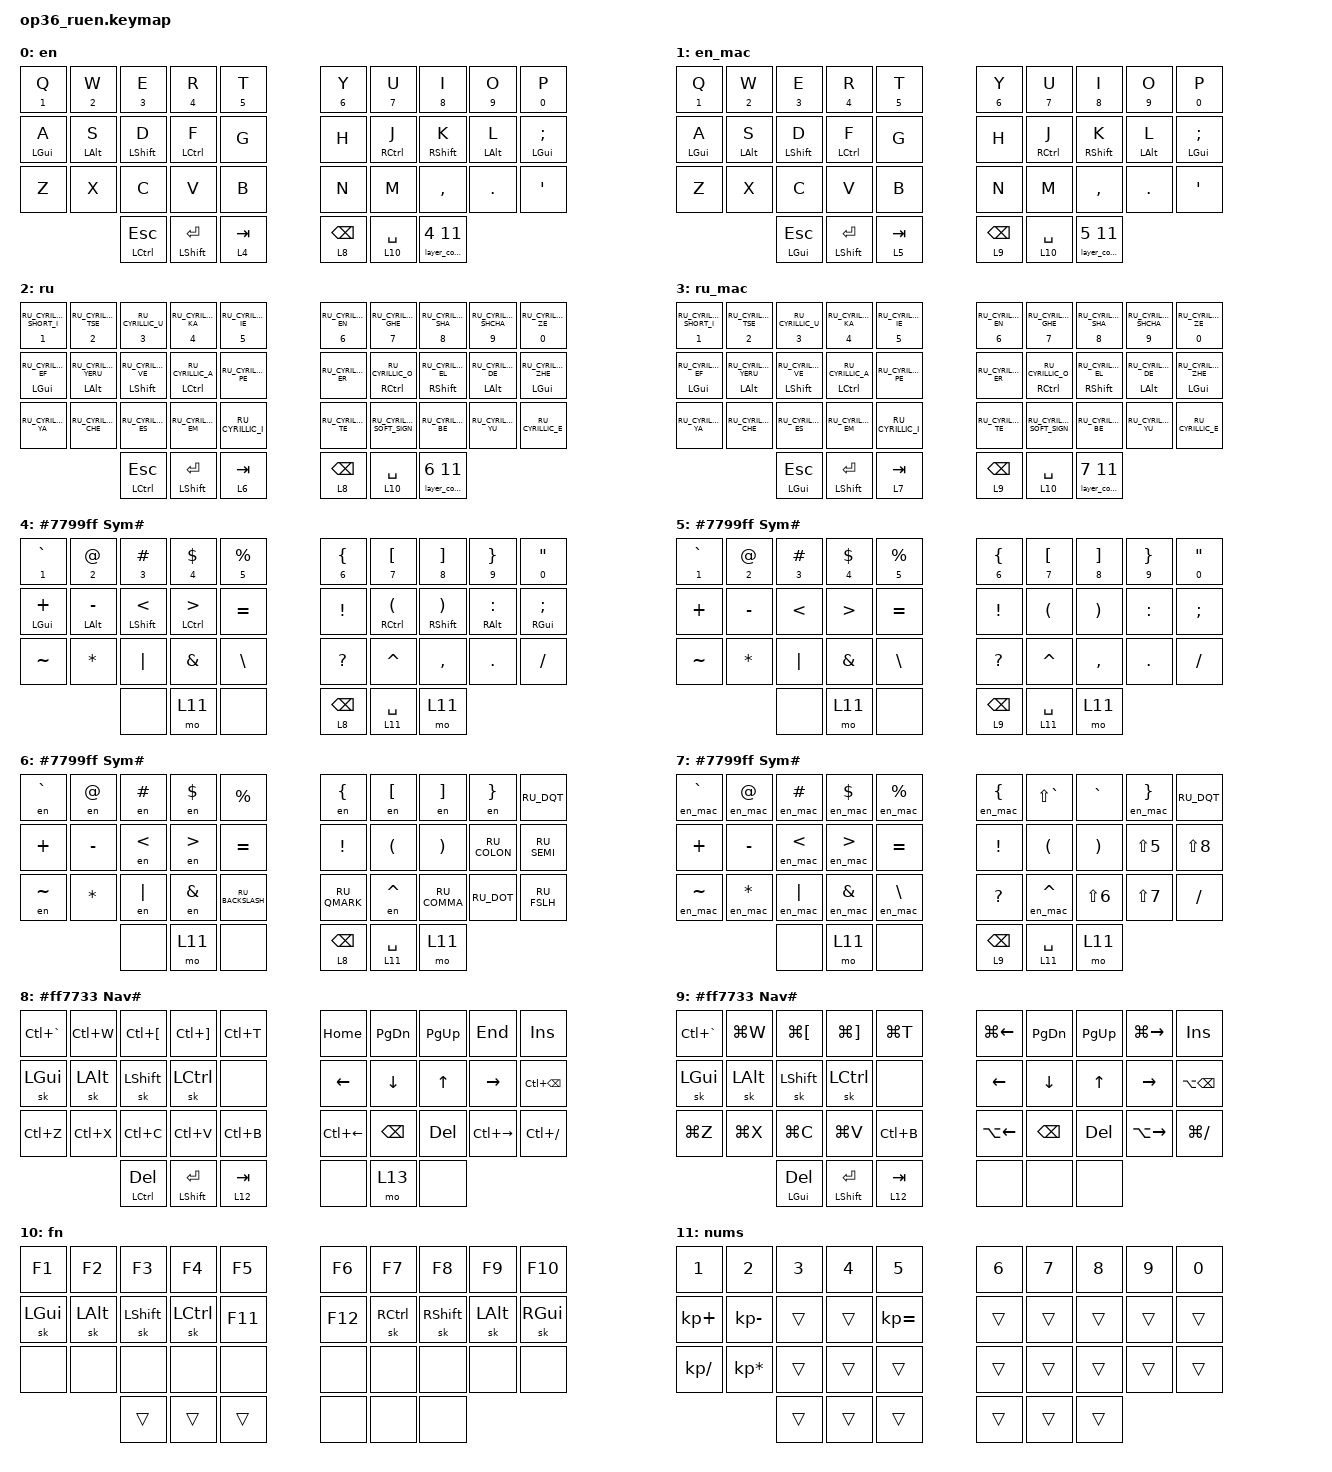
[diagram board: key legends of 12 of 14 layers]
#include "keys_ru.h"
#include <behaviors.dtsi>
#include <dt-bindings/zmk/bt.h>
#include <dt-bindings/zmk/keys.h>
#include <dt-bindings/zmk/outputs.h>
#include <dt-bindings/zmk/pointing.h>

&lt {
    flavor = "balanced";
    tapping-term-ms = <150>;
};

/ {
    behaviors {
        hml: home_row_mod_left {
            compatible = "zmk,behavior-hold-tap";
            #binding-cells = <2>;
            flavor = "balanced";
            require-prior-idle-ms = <150>;
            tapping-term-ms = <200>;
            quick-tap-ms = <175>;
            bindings = <&kp>, <&kp>;

            hold-trigger-key-positions = <5 6 7 8 9 15 16 17 18 19 25 26 27 28 29 33 34 35>;
            hold-trigger-on-release;
        };

        hmr: home_row_mod_right {
            compatible = "zmk,behavior-hold-tap";
            #binding-cells = <2>;
            flavor = "balanced";
            require-prior-idle-ms = <150>;
            tapping-term-ms = <200>;
            quick-tap-ms = <175>;
            bindings = <&kp>, <&kp>;

            hold-trigger-key-positions = <0 1 2 3 4 10 11 12 13 14 20 21 22 23 24 30 31 32>;
            hold-trigger-on-release;
        };

        nm: nm {
            compatible = "zmk,behavior-hold-tap";
            label = "NM";
            bindings = <&kp>, <&kp>;

            #binding-cells = <2>;
            tapping-term-ms = <200>;
            flavor = "balanced";
        };
    };

    combos {
        compatible = "zmk,combos";

        kha {
            bindings = <&kp RU_CYRILLIC_HA>;
            key-positions = <6 7>;
            layers = <2 3>;
        };

        hrdsgn {
            bindings = <&kp RU_CYRILLIC_HARD_SIGN>;
            key-positions = <7 8>;
            layers = <2 3>;
        };

        yo {
            bindings = <&kp RU_CYRILLIC_IO>;
            key-positions = <4 3>;
            layers = <2>;
        };

        yo_mac {
            bindings = <&kp NUBS>;
            key-positions = <4 3>;
            layers = <3>;
        };

        en {
            bindings = <&layer_en>;
            key-positions = <2 1>;
            layers = <2>;
            require-prior-idle-ms = <100>;
        };

        en_none {
            bindings = <&none>;
            key-positions = <2 1>;
            layers = <0 1>;
            require-prior-idle-ms = <100>;
        };

        en_mac {
            bindings = <&layer_en_mac>;
            key-positions = <2 1>;
            layers = <3>;
            require-prior-idle-ms = <100>;
        };

        ru {
            bindings = <&layer_ru>;
            key-positions = <3 2>;
            layers = <0>;
            require-prior-idle-ms = <100>;
        };

        ru_none {
            bindings = <&none>;
            key-positions = <3 2>;
            layers = <3 2>;
            require-prior-idle-ms = <100>;
        };

        ru_mac {
            bindings = <&layer_ru_mac>;
            key-positions = <3 2>;
            layers = <1>;
            require-prior-idle-ms = <100>;
        };

        en_nums {
            bindings = <&layer_combo 4 11>;
            key-positions = <32 31>;
            layers = <0 1>;
        };

        ru_nums {
            bindings = <&layer_combo 6 11>;
            key-positions = <32 31>;
            layers = <2>;
        };

        ru_mac_nums {
            bindings = <&layer_combo 7 11>;
            key-positions = <32 31>;
            layers = <3>;
        };

        underscore {
            bindings = <&kp UNDER>;
            key-positions = <26 27>;
            layers = <0 1 2 3 4 6 7 11>;
        };

        tmux_hor {
            bindings = <&tmux PRCNT>;
            key-positions = <23 24>;
            layers = <8 9>;
        };

        tmux_ver {
            bindings = <&tmux DQT>;
            key-positions = <24 14>;
            layers = <8 9>;
        };

        adj {
            bindings = <&mo 12>;
            key-positions = <32 33>;
            layers = <0 2 1 3>;
        };

        cmb_back {
            bindings = <&kp BACKSPACE>;
            key-positions = <18 19>;
        };

        cmb_enter {
            bindings = <&kp ENTER>;
            key-positions = <28 29>;
        };

        cmb_esc {
            bindings = <&kp ESC>;
            key-positions = <0 1>;
        };

        cmb_minus {
            bindings = <&kp MINUS>;
            key-positions = <22 23>;
        };

        cmb_ctrl_enter {
            bindings = <&kp LC(ENTER)>;
            key-positions = <27 28 29>;
        };

        cmb_ctrl_back {
            bindings = <&kp LC(K_BACK)>;
            key-positions = <17 18 19>;
        };
    };

    macros {
        to_ru: to_ru {
            compatible = "zmk,behavior-macro";
            #binding-cells = <0>;
            bindings = <&kp LG(SPACE)>;
            label = "TO_RU";
            wait-ms = <0>;
            tap-ms = <30>;
        };

        to_en: to_en {
            compatible = "zmk,behavior-macro";
            #binding-cells = <0>;
            bindings = <&kp LG(SPACE)>;
            label = "TO_EN";
            wait-ms = <0>;
            tap-ms = <30>;
        };

        to_en_mac: to_en_mac {
            compatible = "zmk,behavior-macro";
            #binding-cells = <0>;
            bindings = <&kp LC(SPACE)>;
            label = "TO_EN_MAC";
            wait-ms = <0>;
            tap-ms = <30>;
        };

        to_ru_mac: to_ru_mac {
            compatible = "zmk,behavior-macro";
            #binding-cells = <0>;
            bindings = <&kp LC(SPACE)>;
            label = "TO_RU_MAC";
            wait-ms = <0>;
            tap-ms = <30>;
        };

        layer_en: layer_en {
            compatible = "zmk,behavior-macro";
            #binding-cells = <0>;
            bindings = <&to 0 &to_en>;
            label = "LAYER_EN";
            wait-ms = <0>;
            tap-ms = <30>;
        };

        layer_ru: layer_ru {
            compatible = "zmk,behavior-macro";
            #binding-cells = <0>;
            bindings = <&to 2 &to_ru>;
            label = "LAYER_RU";
            wait-ms = <0>;
            tap-ms = <30>;
        };

        layer_en_mac: layer_en_mac {
            compatible = "zmk,behavior-macro";
            #binding-cells = <0>;
            bindings = <&to 1 &to_en_mac>;
            label = "LAYER_EN_MAC";
            wait-ms = <0>;
            tap-ms = <30>;
        };

        layer_ru_mac: layer_ru_mac {
            compatible = "zmk,behavior-macro";
            #binding-cells = <0>;
            bindings = <&to 3 &to_ru_mac>;
            label = "LAYER_RU_MAC";
            wait-ms = <0>;
            tap-ms = <30>;
        };

        en: en {
            compatible = "zmk,behavior-macro-one-param";
            #binding-cells = <1>;
            bindings =
                <&to_en>,
                <&macro_press>,
                <&macro_param_1to1 &kp MACRO_PLACEHOLDER>,
                <&macro_pause_for_release>,
                <&macro_release>,
                <&macro_param_1to1 &kp MACRO_PLACEHOLDER>,
                <&macro_tap>,
                <&to_ru>;

            label = "EN";
            wait-ms = <0>;
            tap-ms = <30>;
        };

        en_mac: en_mac {
            compatible = "zmk,behavior-macro-one-param";
            #binding-cells = <1>;
            bindings = <&to_en_mac &macro_param_1to1 &kp MACRO_PLACEHOLDER &to_ru_mac>;
            label = "EN_MAC";
            wait-ms = <0>;
            tap-ms = <30>;
        };

        bt_pc: bt_pc {
            compatible = "zmk,behavior-macro";
            #binding-cells = <0>;
            bindings = <&to 0 &bt BT_SEL 0>;
            label = "BT_PC";
        };

        bt_mac: bt_mac {
            compatible = "zmk,behavior-macro";
            #binding-cells = <0>;
            bindings = <&to 1 &bt BT_SEL 1>;
            label = "BT_MAC";
        };

        layer_combo: layer_combo {
            compatible = "zmk,behavior-macro-two-param";
            #binding-cells = <2>;
            bindings =
                <&macro_press>,
                <&macro_param_1to1 &mo MACRO_PLACEHOLDER &macro_param_2to1 &mo MACRO_PLACEHOLDER>,
                <&macro_pause_for_release>,
                <&macro_release>,
                <&macro_param_2to1 &mo MACRO_PLACEHOLDER &macro_param_1to1 &mo MACRO_PLACEHOLDER>;

            label = "LAYER_COMBO";
        };

        tmux: tmux {
            compatible = "zmk,behavior-macro-one-param";
            #binding-cells = <1>;
            bindings = <&kp LC(B) &macro_param_1to1 &kp MACRO_PLACEHOLDER>;
            label = "TMUX";
        };
    };

    keymap {
        compatible = "zmk,keymap";

        en {
            display-name = "  Base";
            bindings = <
  &nm N1 Q     &nm N2 W     &nm N3 E      &nm N4 R       &nm N5 T                                     &nm N6 Y      &nm N7 U           &nm N8 I      &nm N9 O     &nm N0 P
  &hml LGUI A  &hml LALT S  &hml LSHFT D  &hml LCTRL F   &kp G                                        &kp H         &hmr RCTRL J       &hmr RSHFT K  &hmr LALT L  &hmr LGUI SEMICOLON
  &kp Z        &kp X        &kp C         &kp V          &kp B                                        &kp N         &kp M              &kp COMMA     &kp DOT      &kp SQT
                                          &mt LCTRL ESC  &mt LSHFT RET  &lt 4 TAB    &lt 8 BACKSPACE  &lt 10 SPACE  &layer_combo 4 11
            >;
        };

        en_mac {
            display-name = " Base";
            bindings = <
  &nm N1 Q     &nm N2 W     &nm N3 E      &nm N4 R      &nm N5 T                                     &nm N6 Y      &nm N7 U           &nm N8 I      &nm N9 O     &nm N0 P
  &hml LGUI A  &hml LALT S  &hml LSHFT D  &hml LCTRL F  &kp G                                        &kp H         &hmr RCTRL J       &hmr RSHFT K  &hmr LALT L  &hmr LGUI SEMICOLON
  &kp Z        &kp X        &kp C         &kp V         &kp B                                        &kp N         &kp M              &kp COMMA     &kp DOT      &kp SQT
                                          &mt LGUI ESC  &mt LSHFT RET  &lt 5 TAB    &lt 9 BACKSPACE  &lt 10 SPACE  &layer_combo 5 11
            >;
        };

        ru {
            display-name = "󱌭 Ru";
            bindings = <
  &nm N1 RU_CYRILLIC_SHORT_I  &nm N2 RU_CYRILLIC_TSE      &nm N3 RU_CYRILLIC_U       &nm N4 RU_CYRILLIC_KA     &nm N5 RU_CYRILLIC_IE                                &nm N6 RU_CYRILLIC_EN  &nm N7 RU_CYRILLIC_GHE     &nm N8 RU_CYRILLIC_SHA     &nm N9 RU_CYRILLIC_SHCHA  &nm N0 RU_CYRILLIC_ZE
  &hml LGUI RU_CYRILLIC_EF    &hml LALT RU_CYRILLIC_YERU  &hml LSHFT RU_CYRILLIC_VE  &hml LCTRL RU_CYRILLIC_A  &kp RU_CYRILLIC_PE                                   &kp RU_CYRILLIC_ER     &hmr RCTRL RU_CYRILLIC_O   &hmr RSHFT RU_CYRILLIC_EL  &hmr LALT RU_CYRILLIC_DE  &hmr LGUI RU_CYRILLIC_ZHE
  &kp RU_CYRILLIC_YA          &kp RU_CYRILLIC_CHE         &kp RU_CYRILLIC_ES         &kp RU_CYRILLIC_EM        &kp RU_CYRILLIC_I                                    &kp RU_CYRILLIC_TE     &kp RU_CYRILLIC_SOFT_SIGN  &kp RU_CYRILLIC_BE         &kp RU_CYRILLIC_YU        &kp RU_CYRILLIC_E
                                                                                     &mt LCTRL ESC             &mt LSHFT RET          &lt 6 TAB    &lt 8 BACKSPACE  &lt 10 SPACE           &layer_combo 6 11
            >;
        };

        ru_mac {
            display-name = " Ru";
            bindings = <
  &nm N1 RU_CYRILLIC_SHORT_I  &nm N2 RU_CYRILLIC_TSE      &nm N3 RU_CYRILLIC_U       &nm N4 RU_CYRILLIC_KA     &nm N5 RU_CYRILLIC_IE                                &nm N6 RU_CYRILLIC_EN  &nm N7 RU_CYRILLIC_GHE     &nm N8 RU_CYRILLIC_SHA     &nm N9 RU_CYRILLIC_SHCHA  &nm N0 RU_CYRILLIC_ZE
  &hml LGUI RU_CYRILLIC_EF    &hml LALT RU_CYRILLIC_YERU  &hml LSHFT RU_CYRILLIC_VE  &hml LCTRL RU_CYRILLIC_A  &kp RU_CYRILLIC_PE                                   &kp RU_CYRILLIC_ER     &hmr RCTRL RU_CYRILLIC_O   &hmr RSHFT RU_CYRILLIC_EL  &hmr LALT RU_CYRILLIC_DE  &hmr LGUI RU_CYRILLIC_ZHE
  &kp RU_CYRILLIC_YA          &kp RU_CYRILLIC_CHE         &kp RU_CYRILLIC_ES         &kp RU_CYRILLIC_EM        &kp RU_CYRILLIC_I                                    &kp RU_CYRILLIC_TE     &kp RU_CYRILLIC_SOFT_SIGN  &kp RU_CYRILLIC_BE         &kp RU_CYRILLIC_YU        &kp RU_CYRILLIC_E
                                                                                     &mt LGUI ESC              &mt LSHFT RET          &lt 7 TAB    &lt 9 BACKSPACE  &lt 10 SPACE           &layer_combo 7 11
            >;
        };

        sym_en {
            display-name = "#7799ff Sym#";
            bindings = <
  &nm N1 GRAVE    &nm N2 AT_SIGN   &nm N3 HASH     &nm N4 DLLR    &nm N5 PRCNT                            &nm N6 LBRC   &nm N7 LBKT      &nm N8 RBKT       &nm N9 RBRC      &nm N0 DQT
  &hml LGUI PLUS  &hml LALT MINUS  &hml LSHIFT LT  &hml LCTRL GT  &kp EQUAL                               &kp EXCL      &hmr RCTRL LPAR  &hmr RSHIFT RPAR  &hmr RALT COLON  &hmr RGUI SEMI
  &kp TILDE       &kp STAR         &kp PIPE        &kp AMPS       &kp BSLH                                &kp QMARK     &kp CARET        &kp COMMA         &kp DOT          &kp FSLH
                                                   &none          &mo 11        &none    &lt 8 BACKSPACE  &lt 11 SPACE  &mo 11
            >;
        };

        sym_en_mac {
            display-name = "#7799ff Sym#";
            bindings = <
  &nm N1 GRAVE  &nm N2 AT_SIGN  &nm N3 HASH  &nm N4 DLLR  &nm N5 PRCNT                            &nm N6 LBRC   &nm N7 LBKT  &nm N8 RBKT  &nm N9 RBRC  &nm N0 DQT
  &kp PLUS      &kp MINUS       &kp LT       &kp GT       &kp EQUAL                               &kp EXCL      &kp LPAR     &kp RPAR     &kp COLON    &kp SEMI
  &kp TILDE     &kp STAR        &kp PIPE     &kp AMPS     &kp BSLH                                &kp QMARK     &kp CARET    &kp COMMA    &kp DOT      &kp FSLH
                                             &none        &mo 11        &none    &lt 9 BACKSPACE  &lt 11 SPACE  &mo 11
            >;
        };

        sym_ru {
            display-name = "#7799ff Sym#";
            bindings = <
  &en GRAVE  &en AT_SIGN  &en HASH  &en DLLR  &kp PRCNT                                   &en LBRC      &en LBKT   &en RBKT      &en RBRC      &kp RU_DQT
  &kp PLUS   &kp MINUS    &en LT    &en GT    &kp EQUAL                                   &kp EXCL      &kp LPAR   &kp RPAR      &kp RU_COLON  &kp RU_SEMI
  &en TILDE  &kp STAR     &en PIPE  &en AMPS  &kp RU_BACKSLASH                            &kp RU_QMARK  &en CARET  &kp RU_COMMA  &kp RU_DOT    &kp RU_FSLH
                                    &none     &mo 11            &none    &lt 8 BACKSPACE  &lt 11 SPACE  &mo 11
            >;
        };

        sym_ru_mac {
            display-name = "#7799ff Sym#";
            bindings = <
  &en_mac GRAVE  &en_mac AT_SIGN  &en_mac HASH  &en_mac DLLR  &en_mac PRCNT                            &en_mac LBRC  &kp LS(GRAVE)  &kp GRAVE   &en_mac RBRC  &kp RU_DQT
  &kp PLUS       &kp MINUS        &en_mac LT    &en_mac GT    &kp EQUAL                                &kp EXCL      &kp LPAR       &kp RPAR    &kp LS(N5)    &kp LS(N8)
  &en_mac TILDE  &en_mac STAR     &en_mac PIPE  &en_mac AMPS  &en_mac BSLH                             &kp QMARK     &en_mac CARET  &kp LS(N6)  &kp LS(N7)    &kp FSLH
                                                &none         &mo 11         &none    &lt 9 BACKSPACE  &lt 11 SPACE  &mo 11
            >;
        };

        nav {
            display-name = "#ff7733 Nav#";
            bindings = <
  &kp LC(GRAVE)  &kp LC(W)  &kp LC(LBKT)  &kp LC(RBKT)   &kp LC(T)                           &kp HOME      &kp PG_DN      &kp PG_UP  &kp END        &kp INS
  &sk LGUI       &sk LALT   &sk LSHFT     &sk LCTRL      &none                               &kp LEFT      &kp DOWN       &kp UP     &kp RIGHT      &kp LC(BACKSPACE)
  &kp LC(Z)      &kp LC(X)  &kp LC(C)     &kp LC(V)      &kp LC(B)                           &kp LC(LEFT)  &kp BACKSPACE  &kp DEL    &kp LC(RIGHT)  &kp LC(FSLH)
                                          &mt LCTRL DEL  &mt LSHFT RET  &lt 12 TAB    &none  &mo 13        &none
            >;
        };

        nav_mac {
            display-name = "#ff7733 Nav#";
            bindings = <
  &kp LC(GRAVE)  &kp LG(W)  &kp LG(LBKT)  &kp LG(RBKT)  &kp LG(T)                           &kp LG(LEFT)  &kp PG_DN      &kp PG_UP  &kp LG(RIGHT)  &kp INS
  &sk LGUI       &sk LALT   &sk LSHFT     &sk LCTRL     &none                               &kp LEFT      &kp DOWN       &kp UP     &kp RIGHT      &kp LA(BACKSPACE)
  &kp LG(Z)      &kp LG(X)  &kp LG(C)     &kp LG(V)     &kp LC(B)                           &kp LA(LEFT)  &kp BACKSPACE  &kp DEL    &kp LA(RIGHT)  &kp LG(FSLH)
                                          &mt LGUI DEL  &mt LSHFT RET  &lt 12 TAB    &none  &none         &none
            >;
        };

        fn {
            display-name = "  Fun";
            bindings = <
  &kp F1    &kp F2    &kp F3     &kp F4     &kp F5                    &kp F6   &kp F7     &kp F8     &kp F9    &kp F10
  &sk LGUI  &sk LALT  &sk LSHFT  &sk LCTRL  &kp F11                   &kp F12  &sk RCTRL  &sk RSHFT  &sk LALT  &sk RGUI
  &none     &none     &none      &none      &none                     &none    &none      &none      &none     &none
                                 &trans     &trans   &trans    &none  &none    &none
            >;
        };

        nums {
            display-name = "󰎠  Num";
            bindings = <
  &kp N1         &kp N2           &kp N3  &kp N4  &kp N5                          &kp N6  &kp N7  &kp N8  &kp N9  &kp N0
  &kp KP_PLUS    &kp KP_MINUS     &trans  &trans  &kp KP_EQUAL                    &trans  &trans  &trans  &trans  &trans
  &kp KP_DIVIDE  &kp KP_MULTIPLY  &trans  &trans  &trans                          &trans  &trans  &trans  &trans  &trans
                                          &trans  &trans        &trans    &trans  &trans  &trans
            >;
        };

        adj {
            display-name = "  Adjust";
            bindings = <
  &bt_pc          &bt_mac       &bt BT_SEL 2  &bt BT_SEL 3  &bt BT_SEL 4                  &kp F23  &kp C_BRI_DN  &kp C_BRI_UP  &kp F24     &kp PRINTSCREEN
  &bt BT_CLR      &out OUT_USB  &out OUT_BLE  &none         &none                         &none    &kp C_VOL_DN  &kp C_VOL_UP  &kp C_MUTE  &kp LA(PRINTSCREEN)
  &studio_unlock  &none         &kp CAPS      &none         &none                         &none    &kp C_PREV    &kp C_NEXT    &kp C_PP    &kp LS(PRINTSCREEN)
                                              &none         &none         &none    &none  &none    &none
            >;
        };

        mouse {
            display-name = "Mouse";
            bindings = <
  &none  &none     &none     &none     &none                  &msc SCRL_LEFT  &msc SCRL_DOWN  &msc SCRL_UP  &msc SCRL_RIGHT  &none
  &none  &mkp MB3  &mkp MB2  &mkp MB1  &none                  &mmv MOVE_LEFT  &mmv MOVE_DOWN  &mmv MOVE_UP  &mmv MOVE_RIGHT  &none
  &none  &none     &none     &none     &none                  &none           &none           &none         &none            &none
                             &none     &none  &none    &none  &none           &none
            >;
        };
    };

    conditional_layers { compatible = "zmk,conditional-layers"; };
};
